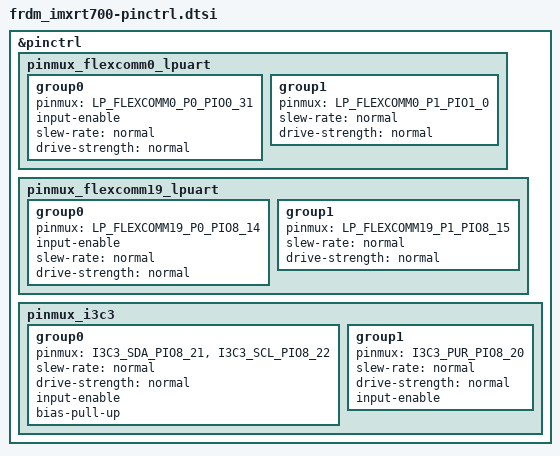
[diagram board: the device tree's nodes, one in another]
/*
 * Copyright 2026 NXP
 * SPDX-License-Identifier: Apache-2.0
 */

#include <nxp/imxrt/imxrt7xx/pinctrl/MIMXRT798SGFOB-pinctrl.h>

&pinctrl {
	/* CPU0 debug console (MCU-Link), FLEXCOMM0 LPUART - same pins as MIMXRT700-EVK */
	pinmux_flexcomm0_lpuart: pinmux_flexcomm0_lpuart {
		group0 {
			pinmux = <LP_FLEXCOMM0_P0_PIO0_31>;
			input-enable;
			slew-rate = "normal";
			drive-strength = "normal";
		};

		group1 {
			pinmux = <LP_FLEXCOMM0_P1_PIO1_0>;
			slew-rate = "normal";
			drive-strength = "normal";
		};
	};

	/* CPU1 debug console, FLEXCOMM19 LPUART - same pins as MIMXRT700-EVK */
	pinmux_flexcomm19_lpuart: pinmux_flexcomm19_lpuart {
		group0 {
			pinmux = <LP_FLEXCOMM19_P0_PIO8_14>;
			input-enable;
			slew-rate = "normal";
			drive-strength = "normal";
		};

		group1 {
			pinmux = <LP_FLEXCOMM19_P1_PIO8_15>;
			slew-rate = "normal";
			drive-strength = "normal";
		};
	};

	/* I3C3 to the on-board P3T2175DP temperature sensor (U1) */
	pinmux_i3c3: pinmux_i3c3 {
		group0 {
			pinmux = <I3C3_SDA_PIO8_21>,
				 <I3C3_SCL_PIO8_22>;
			slew-rate = "normal";
			drive-strength = "normal";
			input-enable;
			bias-pull-up;
		};

		group1 {
			pinmux = <I3C3_PUR_PIO8_20>;
			slew-rate = "normal";
			drive-strength = "normal";
			input-enable;
		};
	};
};
